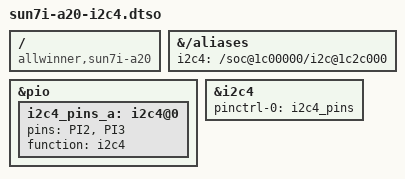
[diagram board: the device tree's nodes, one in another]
/dts-v1/;
/plugin/;

/ {
	compatible = "allwinner,sun7i-a20";

	fragment@0 {
		target-path = "/aliases";
		__overlay__ {
			i2c4 = "/soc@1c00000/i2c@1c2c000";
		};
	};

	fragment@1 {
		target = <&pio>;
		__overlay__ {
			i2c4_pins_a: i2c4@0 {
				pins = "PI2", "PI3";
				function = "i2c4";
			};
		};
	};

	fragment@2 {
		target = <&i2c4>;
		__overlay__ {
			pinctrl-names = "default";
			pinctrl-0 = <&i2c4_pins>;
			status = "okay";
		};
	};
};
